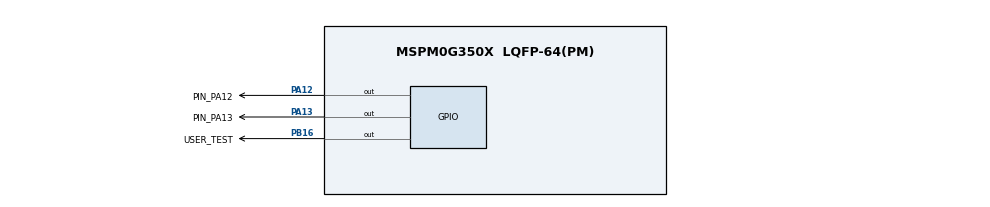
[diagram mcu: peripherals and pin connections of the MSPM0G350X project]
/**
 * @cliArgs --device "MSPM0G350X" --part "Default" --package "LQFP-64(PM)" --product "mspm0_sdk@2.10.00.04"
 * @versions {"tool":"1.26.2+4477"}
 */

/**
 * Import the modules used in this configuration.
 */
const GPIO   = scripting.addModule("/ti/driverlib/GPIO", {}, false);
const GPIO1  = GPIO.addInstance();
const GPIO2  = GPIO.addInstance();
const SYSCTL = scripting.addModule("/ti/driverlib/SYSCTL");

/**
 * Write custom configuration values to the imported modules.
 */
GPIO1.$name                         = "GPIO_LEDS";
GPIO1.port                          = "PORTB";
GPIO1.associatedPins.create(4);
GPIO1.associatedPins[0].$name       = "USER_LED_1";
GPIO1.associatedPins[0].assignedPin = "22";
GPIO1.associatedPins[1].$name       = "USER_LED_2";
GPIO1.associatedPins[1].assignedPin = "26";
GPIO1.associatedPins[2].$name       = "USER_LED_3";
GPIO1.associatedPins[2].assignedPin = "27";
GPIO1.associatedPins[3].$name       = "USER_TEST";
GPIO1.associatedPins[3].pin.$assign = "PB16";

const Board = scripting.addModule("/ti/driverlib/Board", {}, false);

GPIO2.$name                         = "GPIO_CAN_TEST";
GPIO2.port                          = "PORTA";
GPIO2.associatedPins.create(2);
GPIO2.associatedPins[0].$name       = "PIN_PA12";
GPIO2.associatedPins[0].pin.$assign = "PA12";
GPIO2.associatedPins[1].$name       = "PIN_PA13";
GPIO2.associatedPins[1].pin.$assign = "PA13";

SYSCTL.forceDefaultClkConfig = true;
SYSCTL.clockTreeEn           = true;

/**
 * Pinmux solution for unlocked pins/peripherals. This ensures that minor changes to the automatic solver in a future
 * version of the tool will not impact the pinmux you originally saw.  These lines can be completely deleted in order to
 * re-solve from scratch.
 */
GPIO1.associatedPins[0].pin.$suggestSolution = "PB22";
GPIO1.associatedPins[1].pin.$suggestSolution = "PB26";
GPIO1.associatedPins[2].pin.$suggestSolution = "PB27";
Board.peripheral.$suggestSolution            = "DEBUGSS";
Board.peripheral.swclkPin.$suggestSolution   = "PA20";
Board.peripheral.swdioPin.$suggestSolution   = "PA19";
